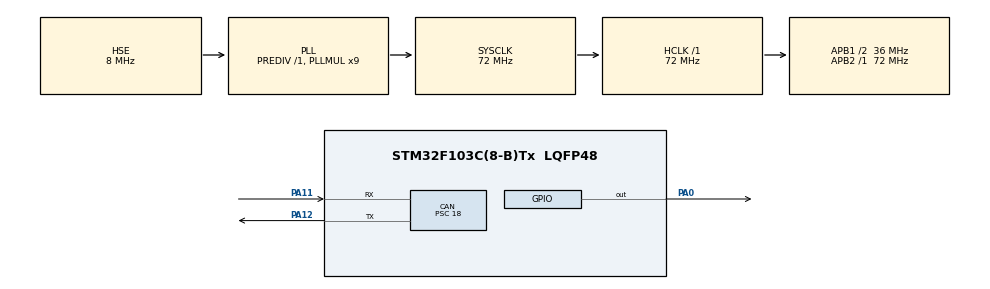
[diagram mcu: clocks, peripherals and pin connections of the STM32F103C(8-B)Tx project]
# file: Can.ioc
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CAN.BS1=CAN_BS1_2TQ
CAN.CalculateBaudRate=500000
CAN.CalculateTimeBit=2000.00
CAN.CalculateTimeQuantum=500.0
CAN.Mode=CAN_MODE_NORMAL
CAN.NART=DISABLE
CAN.Prescaler=18
CAN.SJW=CAN_SJW_1TQ
Mcu.Family=STM32F1
Mcu.Name=STM32F103C(8-B)Tx
Mcu.Package=LQFP48
NVIC.CAN1_RX1_IRQn=true\:0\:0\:false\:false\:true\:true\:true
NVIC.PriorityGroup=NVIC_PRIORITYGROUP_4
NVIC.USB_LP_CAN1_RX0_IRQn=true\:0\:0\:false\:false\:true\:true\:true
PA0-WKUP.Signal=GPIO_Output
PA11.Mode=CAN_Activate
PA11.Signal=CAN_RX
PA12.Mode=CAN_Activate
PA12.Signal=CAN_TX
PA13.Mode=Serial_Wire
PA13.Signal=SYS_JTMS-SWDIO
PA14.Mode=Serial_Wire
PA14.Signal=SYS_JTCK-SWCLK
PD0-OSC_IN.Mode=HSE-External-Oscillator
PD0-OSC_IN.Signal=RCC_OSC_IN
PD1-OSC_OUT.Mode=HSE-External-Oscillator
PD1-OSC_OUT.Signal=RCC_OSC_OUT
ProjectManager.HeapSize=0x200
ProjectManager.StackSize=0x400
ProjectManager.TargetToolchain=STM32CubeIDE
RCC.AHBFreq_Value=72000000
RCC.APB1CLKDivider=RCC_HCLK_DIV2
RCC.APB1Freq_Value=36000000
RCC.APB1TimFreq_Value=72000000
RCC.APB2Freq_Value=72000000
RCC.APB2TimFreq_Value=72000000
RCC.HCLKFreq_Value=72000000
RCC.PLLMUL=RCC_PLL_MUL9
RCC.PLLSourceVirtual=RCC_PLLSOURCE_HSE
RCC.SYSCLKFreq_VALUE=72000000
RCC.SYSCLKSource=RCC_SYSCLKSOURCE_PLLCLK
RCC.USBFreq_Value=72000000
board=custom

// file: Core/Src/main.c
/* USER CODE BEGIN Header */
/**
  ******************************************************************************
  * @file           : main.c
  * @brief          : Main program body
  ******************************************************************************
  * @attention
  *
  * <h2><center>&copy; Copyright (c) 2022 STMicroelectronics.
  * All rights reserved.</center></h2>
  *
  * This software component is licensed by ST under BSD 3-Clause license,
  * the "License"; You may not use this file except in compliance with the
  * License. You may obtain a copy of the License at:
  *                        opensource.org/licenses/BSD-3-Clause
  *
  ******************************************************************************
  */
/* USER CODE END Header */
#include "main.h"

CAN_HandleTypeDef hcan;

void SystemClock_Config(void);
static void MX_GPIO_Init(void);
static void MX_CAN_Init(void);

/* USER CODE BEGIN 0 */

CAN_FilterTypeDef canFilterConfig;
CAN_TxHeaderTypeDef tx;
CAN_RxHeaderTypeDef rx;

uint32_t mailbox;

uint8_t txData[8];
uint8_t rxData[8];

uint8_t count;

/* USER CODE END 0 */

int main(void)
{

  /* MCU Configuration--------------------------------------------------------*/

  /* Reset of all peripherals, Initializes the Flash interface and the Systick. */
  HAL_Init();

  /* Configure the system clock */
  SystemClock_Config();

  /* Initialize all configured peripherals */
  MX_GPIO_Init();
  MX_CAN_Init();
  /* USER CODE BEGIN 2 */

  canFilterConfig.FilterActivation = CAN_FILTER_ENABLE; // Ativa ou desativa filtros
  canFilterConfig.FilterBank = 10; // Qual FilterBank será utilizado (0 - 13)
  canFilterConfig.FilterFIFOAssignment = CAN_RX_FIFO0;
  canFilterConfig.FilterIdHigh = 0;
  canFilterConfig.FilterIdLow = 0x0000;
  canFilterConfig.FilterMaskIdHigh = 0;
  canFilterConfig.FilterMaskIdLow = 0x0000;
  canFilterConfig.FilterMode = CAN_FILTERMODE_IDMASK;
  canFilterConfig.FilterScale = CAN_FILTERSCALE_32BIT;

  HAL_CAN_ConfigFilter(&hcan, &canFilterConfig);

  HAL_CAN_Start(&hcan);

  HAL_CAN_ActivateNotification(&hcan, CAN_IT_RX_FIFO0_MSG_PENDING);

  tx.DLC = 2;
  tx.IDE = CAN_ID_STD;
  tx.RTR = CAN_RTR_DATA;
  tx.StdId = 0x103;

  txData[0] = 0xf3;

//  HAL_CAN_AddTxMessage(&hcan, &tx, txData, &mailbox);

  /* USER CODE END 2 */

  /* Infinite loop */
  /* USER CODE BEGIN WHILE */
  while (1)
  {

//	  HAL_GPIO_WritePin(GPIOA, GPIO_PIN_0, GPIO_PIN_RESET);
//
//	  HAL_Delay(1000);
//
//	  HAL_GPIO_WritePin(GPIOA, GPIO_PIN_0, GPIO_PIN_SET);
//
//	  HAL_Delay(1000);

    /* USER CODE END WHILE */

  }
}

void SystemClock_Config(void)
{
  RCC_OscInitTypeDef RCC_OscInitStruct = {0};
  RCC_ClkInitTypeDef RCC_ClkInitStruct = {0};

  /** Initializes the RCC Oscillators according to the specified parameters
  * in the RCC_OscInitTypeDef structure.
  */
  RCC_OscInitStruct.OscillatorType = RCC_OSCILLATORTYPE_HSE;
  RCC_OscInitStruct.HSEState = RCC_HSE_ON;
  RCC_OscInitStruct.HSEPredivValue = RCC_HSE_PREDIV_DIV1;
  RCC_OscInitStruct.HSIState = RCC_HSI_ON;
  RCC_OscInitStruct.PLL.PLLState = RCC_PLL_ON;
  RCC_OscInitStruct.PLL.PLLSource = RCC_PLLSOURCE_HSE;
  RCC_OscInitStruct.PLL.PLLMUL = RCC_PLL_MUL9;
  if (HAL_RCC_OscConfig(&RCC_OscInitStruct) != HAL_OK)
  {
    Error_Handler();
  }
  /** Initializes the CPU, AHB and APB buses clocks
  */
  RCC_ClkInitStruct.ClockType = RCC_CLOCKTYPE_HCLK|RCC_CLOCKTYPE_SYSCLK
                              |RCC_CLOCKTYPE_PCLK1|RCC_CLOCKTYPE_PCLK2;
  RCC_ClkInitStruct.SYSCLKSource = RCC_SYSCLKSOURCE_PLLCLK;
  RCC_ClkInitStruct.AHBCLKDivider = RCC_SYSCLK_DIV1;
  RCC_ClkInitStruct.APB1CLKDivider = RCC_HCLK_DIV2;
  RCC_ClkInitStruct.APB2CLKDivider = RCC_HCLK_DIV1;

  if (HAL_RCC_ClockConfig(&RCC_ClkInitStruct, FLASH_LATENCY_2) != HAL_OK)
  {
    Error_Handler();
  }
}

static void MX_CAN_Init(void)
{

  hcan.Instance = CAN1;
  hcan.Init.Prescaler = 18;
  hcan.Init.Mode = CAN_MODE_NORMAL;
  hcan.Init.SyncJumpWidth = CAN_SJW_1TQ;
  hcan.Init.TimeSeg1 = CAN_BS1_2TQ;
  hcan.Init.TimeSeg2 = CAN_BS2_1TQ;
  hcan.Init.TimeTriggeredMode = DISABLE;
  hcan.Init.AutoBusOff = DISABLE;
  hcan.Init.AutoWakeUp = DISABLE;
  hcan.Init.AutoRetransmission = DISABLE;
  hcan.Init.ReceiveFifoLocked = DISABLE;
  hcan.Init.TransmitFifoPriority = DISABLE;
  if (HAL_CAN_Init(&hcan) != HAL_OK)
  {
    Error_Handler();
  }

}

static void MX_GPIO_Init(void)
{
  GPIO_InitTypeDef GPIO_InitStruct = {0};

  /* GPIO Ports Clock Enable */
  __HAL_RCC_GPIOD_CLK_ENABLE();
  __HAL_RCC_GPIOA_CLK_ENABLE();

  /*Configure GPIO pin Output Level */
  HAL_GPIO_WritePin(GPIOA, GPIO_PIN_0, GPIO_PIN_RESET);

  /*Configure GPIO pin : PA0 */
  GPIO_InitStruct.Pin = GPIO_PIN_0;
  GPIO_InitStruct.Mode = GPIO_MODE_OUTPUT_PP;
  GPIO_InitStruct.Pull = GPIO_NOPULL;
  GPIO_InitStruct.Speed = GPIO_SPEED_FREQ_LOW;
  HAL_GPIO_Init(GPIOA, &GPIO_InitStruct);

}

/* USER CODE BEGIN 4 */

void HAL_CAN_RxFifo0MsgPendingCallback(CAN_HandleTypeDef *hcan) {
	HAL_GPIO_TogglePin(GPIOA, GPIO_PIN_0);
	HAL_CAN_GetRxMessage(hcan, CAN_RX_FIFO0, &rx, rxData);
	count++;
}

//void CAN_Setup(void){
////---------Configurações de filtro e máscara---------
//
//	set_Filter_up.FilterIdHigh = 0;
//	set_Filter_up.FilterIdLow = 0;
//	set_Filter_up.FilterMaskIdHigh = 0;
//	set_Filter_up.FilterMaskIdLow = 0;
//	set_Filter_up.FilterFIFOAssignment = CAN_FILTER_FIFO0;
//	set_Filter_up.FilterBank = 0;
//	set_Filter_up.FilterMode = CAN_FILTERMODE_IDMASK;
//	set_Filter_up.FilterScale = CAN_FILTERSCALE_32BIT;
//	set_Filter_up.FilterActivation = ENABLE;
//	HAL_CAN_ConfigFilter(&hcan, &set_Filter_up);
//
////---------Configurações do envio--------------------
//
//	TxHeader.IDE = CAN_ID_STD;
//	TxHeader.RTR = CAN_RTR_DATA;
//
////---------Início do funcionamento CAN---------------
//
//	HAL_CAN_Start(&hcan);
//	HAL_CAN_ActivateNotification(&hcan, CAN_IT_RX_FIFO0_MSG_PENDING);
//
//}

//void Tx_Send ( uint32_t Id , uint32_t Dlc , int can_request ){
//
//	if ( can_request == False ){
//		TxHeader.StdId = Id;
//		TxHeader.DLC = Dlc;
//	}else{
//		TxHeader.StdId = Id;
//		TxHeader.DLC = Dlc;
//		HAL_CAN_AddTxMessage(&hcan, &TxHeader, &dummy, &TxMailbox);
//	}
//
//
//}
//
//
//void Can_Rx_Wait(){
//	while(flag_can);
//	flag_can = 1;
//}
//
//
//void Tel_Send(void){
//
//	int i;
//
//	for ( i = 0 ; i < 4 ; i++ ){
//		Tx_Send ( 0x610 + i , 8 , False );
//		HAL_CAN_AddTxMessage(&hcan, &TxHeader, (uint8_t*)&Tel_data[8*i], &TxMailbox);
//	}
//
//	flag_tel = 1;
//
//}

/**
 * @brief           CAN Filter Configuration
 * @param[in]
 * @return
 */
void CAN_Filter_Config(void)
{
    CAN_FilterTypeDef  sFilterConfig;

    /*Configure CAN filters*/
    sFilterConfig.FilterBank = 0;
    sFilterConfig.FilterMode = CAN_FILTERMODE_IDMASK;
    sFilterConfig.FilterScale = CAN_FILTERSCALE_32BIT;
    sFilterConfig.FilterIdHigh = 0x0000;
    sFilterConfig.FilterIdLow = 0x0000;
    sFilterConfig.FilterMaskIdHigh = 0x0000;
    sFilterConfig.FilterMaskIdLow = 0x0000;
    sFilterConfig.FilterFIFOAssignment = CAN_RX_FIFO0;
    sFilterConfig.FilterActivation = ENABLE;
    sFilterConfig.SlaveStartFilterBank = 14;

    //Filter Configuration
    if (HAL_CAN_ConfigFilter(&hcan, &sFilterConfig) != HAL_OK)
    {
        while(1){}
    }

    //Start CAN peripherals
    if (HAL_CAN_Start(&hcan) != HAL_OK)
    {
        while(1){}
    }

    //Activation can RX notification
    if (HAL_CAN_ActivateNotification(&hcan, CAN_IT_RX_FIFO0_MSG_PENDING) != HAL_OK)
    {
        while(1){}
    }
}

/**
 * @brief           CAN Send a set of data
 * @param[in]       msg: Data to be sent (maximum 8 bytes)
 * @param[in]       len: Length of data frame (maximum 8)
 * @param[in]       std_id: CAN_ID
 * @return          0: Send Success 1: Send Failure
 */
uint8_t CAN_Send_Msg(uint8_t* msg, uint8_t len, uint8_t std_id)
{
    CAN_TxHeaderTypeDef	can_tx_header;
	uint32_t TxMailbox;
    can_tx_header.StdId = std_id;
    can_tx_header.IDE = CAN_ID_STD;
    can_tx_header.RTR = CAN_RTR_DATA;
    can_tx_header.TransmitGlobalTime = ENABLE;
    can_tx_header.DLC = len;
    //MailboxesFreeLevel = HAL_CAN_GetTxMailboxesFreeLevel(&hcan);
    while(HAL_CAN_GetTxMailboxesFreeLevel(&hcan)==0);
    if(HAL_CAN_AddTxMessage(&hcan, &can_tx_header, msg, &TxMailbox) != HAL_OK)//Send out
	{
		return 1;
	}
    return 0;
}

uint8_t can_rec_dat[8];

//void HAL_CAN_RxFifo0MsgPendingCallback(CAN_HandleTypeDef *hcan)
//{
//    CAN_RxHeaderTypeDef	can_rx_header;      //Receive
//    if(hcan->Instance == CAN1)
//    {
//        HAL_CAN_GetRxMessage(hcan,CAN_FILTER_FIFO0,&can_rx_header,can_rec_dat);
//    }
//}

/* USER CODE END 4 */

void Error_Handler(void)
{
  __disable_irq();
  while (1)
  {
  }
}

/************************ (C) COPYRIGHT STMicroelectronics *****END OF FILE****/
